# MB9BF11xT register map
File version: 1.7
Registers are 32-bit, read-write, reset 0x0 unless marked. A register's access mark holds for its fields unless they carry their own. Offsets are from the block's base; [hi:lo] are bit positions; {n}, {i} and the like mark numbered series; 'fields as' and 'values as' point back to an identical list.

## WC — Watch Counter
Base 0x4003A000
0x00 WCRD 8-bit ro — Watch Counter Read Register
  [5:0] CTR — counter value
0x01 WCRL 8-bit — Watch Counter Reload Register
  [5:0] RLC — reload value
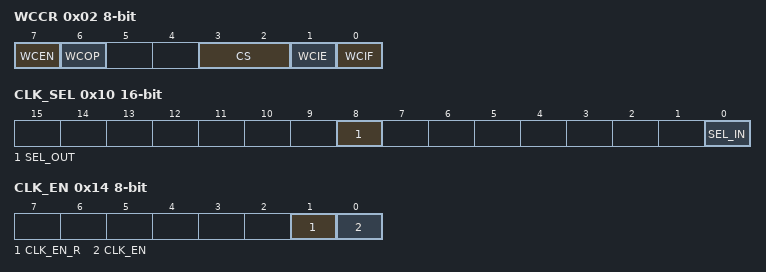
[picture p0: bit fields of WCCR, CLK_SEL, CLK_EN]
0x02 WCCR 8-bit — Watch Counter Control Register
  [7] WCEN — Watch counter operation enable bit
  [6] WCOP ro — Watch counter operating state flag
  [3:2] CS — Count clock select bits
  [1] WCIE — Interrupt request enable bit
  [0] WCIF — Interrupt request flag bit
0x10 CLK_SEL 16-bit — Clock Selection Register
  [8] SEL_OUT — Output clock selection bit
  [0] SEL_IN — Input clock selection bit
0x14 CLK_EN 8-bit — Division Clock Enable Register
  [1] CLK_EN_R — Division clock enable read bit
  [0] CLK_EN — Division clock enable bit

## EXTI — External Interrupt and NMI Control
Base 0x40030000
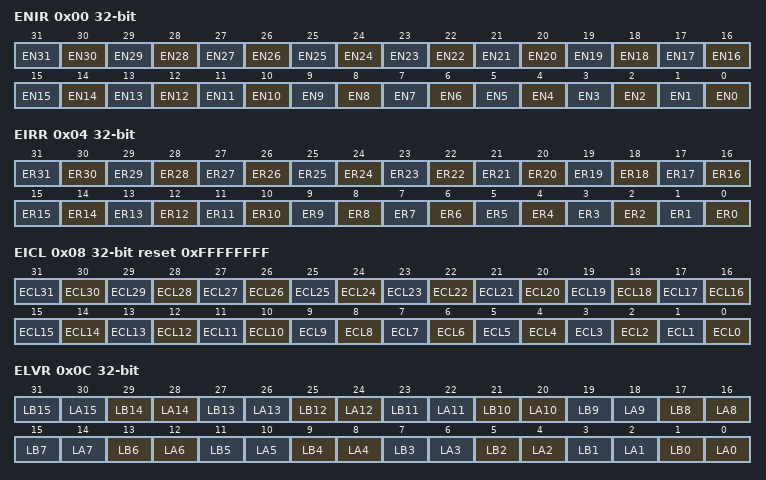
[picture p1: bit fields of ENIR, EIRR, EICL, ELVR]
0x00 ENIR — Enable Interrupt Request Register
  [n] EN{n} (n=0..31) — Bit{n} of ENIR
0x04 EIRR ro reset not defined — External Interrupt Request Register
  [n] ER{n} (n=0..31) — Bit{n} of EIRR
0x08 EICL reset 0xFFFFFFFF — External Interrupt Clear Register
  [n] ECL{n} (n=0..31) — Bit{n} of EICL
0x0C ELVR — External Interrupt Level Register
  [2n+1] LB{n} (n=0..15) — Bit{2n+1} of ELVR
  [2n] LA{n} (n=0..15) — Bit{2n} of ELVR
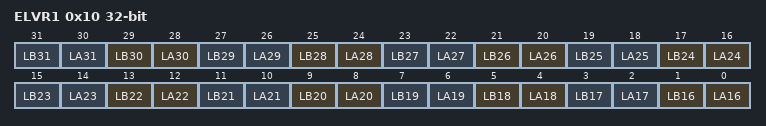
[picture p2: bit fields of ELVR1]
0x10 ELVR1 — External Interrupt Level Register 1
  [2n-31] LB{n} (n=16..31) — Bit{2n-31} of ELVR1
  [2n-32] LA{n} (n=16..31) — Bit{2n-32} of ELVR1
0x14 NMIRR 8-bit ro — Non Maskable Interrupt Request Register
  [0] NR — NMI interrupt request detection bit
0x18 NMICL 8-bit reset 0x1 — Non Maskable Interrupt Clear Register
  [0] NCL — NMI interrupt cause clear bit

## LVD — Low-voltage Detection
Base 0x40035000
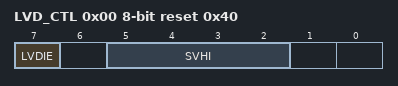
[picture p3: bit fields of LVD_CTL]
0x00 LVD_CTL 8-bit reset 0x40 — Low-voltage Detection Voltage Control Register
  [7] LVDIE — Low-voltage detection interrupt enable bit
  [5:2] SVHI — Low-voltage detection interrupt voltage setting bits
0x04 LVD_STR 8-bit ro — Low-voltage Detection Interrupt Register
  [7] LVDIR — Low-voltage detection interrupt bit
0x08 LVD_CLR 8-bit reset 0x80 — Low-voltage Detection Interrupt Clear Register
  [7] LVDCL — Low-voltage detection interrupt clear bit
0x0C LVD_RLR reset 0x1 — Low-voltage Detection Voltage Protection Register
  [31:0] LVDLCK — Low-voltage Detection Voltage Control Register protection bits
0x10 LVD_STR2 8-bit ro reset 0x40 — Low-voltage Detection Circuit Status Register
  [7] LVDIRDY — Low-voltage detection interrupt status flag

## MFS_NFC — I2C Auxiliary Noise Filter Setting Register
Base 0x40038800
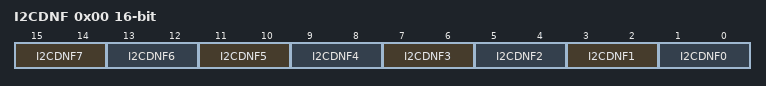
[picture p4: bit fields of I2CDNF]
0x00 I2CDNF 16-bit — I2C Auxiliary Noise Filter Setting Register
  [15:14] I2CDNF7 — Auxiliary noise filter additional step select bits for I2C ch.7
  [13:12] I2CDNF6 — Auxiliary noise filter additional step select bits for I2C ch.6
  [11:10] I2CDNF5 — Auxiliary noise filter additional step select bits for I2C ch.5
  [9:8] I2CDNF4 — Auxiliary noise filter additional step select bits for I2C ch.4
  [7:6] I2CDNF3 — Auxiliary noise filter additional step select bits for I2C ch.3
  [5:4] I2CDNF2 — Auxiliary noise filter additional step select bits for I2C ch.2
  [3:2] I2CDNF1 — Auxiliary noise filter additional step select bits for I2C ch.1
  [1:0] I2CDNF0 — Auxiliary noise filter additional step select bits for I2C ch.0

## CRC — CRC Registers
Base 0x40039000
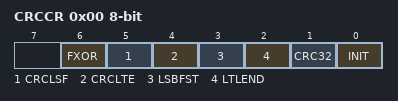
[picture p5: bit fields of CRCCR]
0x00 CRCCR 8-bit — CRC Control Register
  [6] FXOR — Initialization bit
  [5] CRCLSF — Final XOR control bit
  [4] CRCLTE — CRC result bit-order setting bit
  [3] LSBFST — CRC result byte-order setting bit
  [2] LTLEND — Bit-order setting bit
  [1] CRC32 — Byte-order setting bit
  [0] INIT — CRC mode selection bit
0x04 CRCINIT reset 0xFFFFFFFF — Initial Value Register
  [31:0] D — Initial value
0x08 CRCIN — Input Data Register
  [31:0] D — Input data
0x0C CRCR ro reset 0xFFFFFFFF — CRC Register
  [31:0] D — CRC Data

## EXBUS — External Bus Interface
Base 0x4003F000
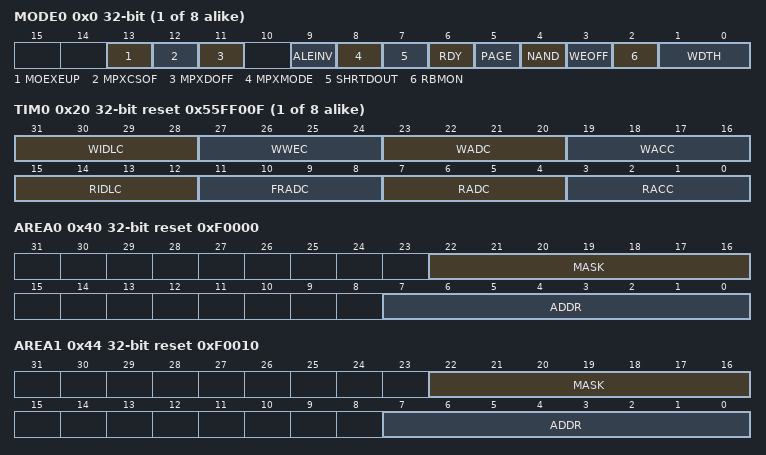
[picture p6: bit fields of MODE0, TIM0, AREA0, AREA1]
{0x0+4i} MODE{i} (i=0..7) — Mode Register {i}
  [13] MOEXEUP — select how to set the MOEX width
  [12] MPXCSOF — select a CS assertion from the start of accessing to the end of address output
  [11] MPXDOFF — select whether or not the address is output to the data lines in multiplex mode
  [9] ALEINV — set up the polarity of the ALE signal
  [8] MPXMODE — select operation bus mode
  [7] SHRTDOUT — select to which idle cycle the write data output is extended
  [6] RDY — control the external RDY function
  [5] PAGE — NOR Flash memory page access mode
  [4] NAND — NAND Flash memory mode
  [3] WEOFF — disable the write enable signal (MWEX) operation
  [2] RBMON — Read Byte Mask ON
  [1:0] WDTH — specify Data Width
{0x20+4i} TIM{i} reset 0x55FF00F (i=0..7) — Timing Register {i}
  [31:28] WIDLC — Write Idle Cycle
  [27:24] WWEC — Write Enable Cycle
  [23:20] WADC — Write Address Setup cycle
  [19:16] WACC — Write Access Cycle
  [15:12] RIDLC — Read Idle Cycle
  [11:8] FRADC — First Read Address Cycle
  [7:4] RADC — Read Address Setup cycle
  [3:0] RACC — Read Access Cycle
0x40 AREA0 reset 0xF0000 — Area Register 0
  [22:16] MASK — address mask
  [7:0] ADDR — Address
0x44 AREA1 reset 0xF0010 — Area Register 1
  [22:16] MASK — address mask
  [7:0] ADDR — Address
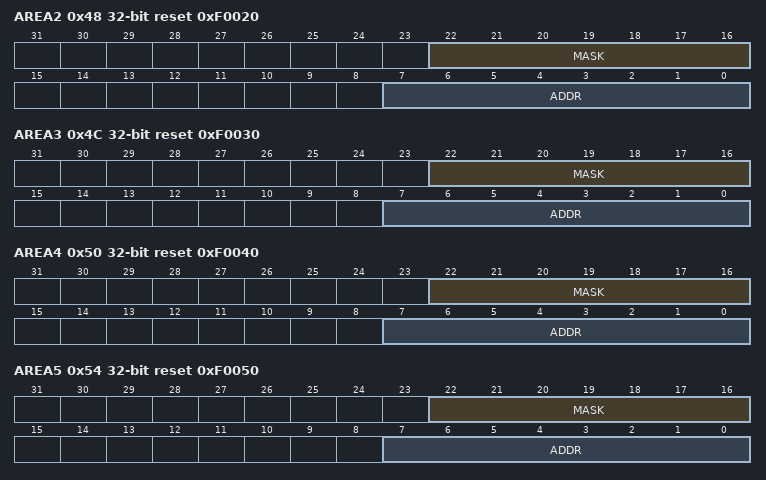
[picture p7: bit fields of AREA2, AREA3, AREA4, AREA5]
0x48 AREA2 reset 0xF0020 — Area Register 2
  [22:16] MASK — address mask
  [7:0] ADDR — Address
0x4C AREA3 reset 0xF0030 — Area Register 3
  [22:16] MASK — address mask
  [7:0] ADDR — Address
0x50 AREA4 reset 0xF0040 — Area Register 4
  [22:16] MASK — address mask
  [7:0] ADDR — Address
0x54 AREA5 reset 0xF0050 — Area Register 5
  [22:16] MASK — address mask
  [7:0] ADDR — Address
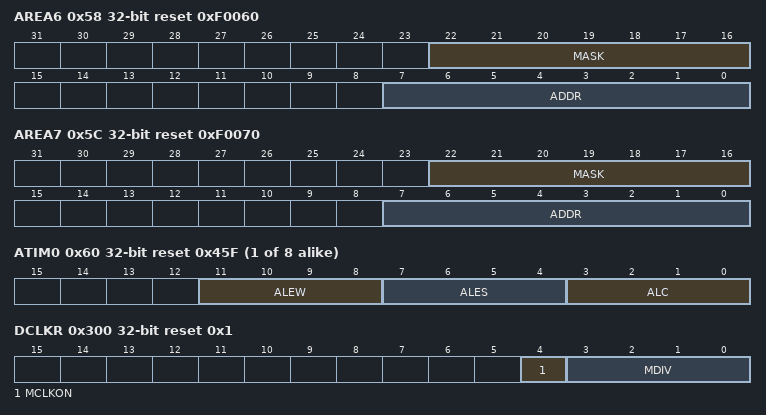
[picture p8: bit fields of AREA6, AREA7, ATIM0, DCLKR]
0x58 AREA6 reset 0xF0060 — Area Register 6
  [22:16] MASK — address mask
  [7:0] ADDR — Address
0x5C AREA7 reset 0xF0070 — Area Register 7
  [22:16] MASK — address mask
  [7:0] ADDR — Address
{0x60+4i} ATIM{i} reset 0x45F (i=0..7) — ALE Timing Register {i}
  [11:8] ALEW — Address Latch Enable Width
  [7:4] ALES — Address Latch Enable Setup cycle
  [3:0] ALC — Address Latch Cycle
0x300 DCLKR reset 0x1 (reset mask 0xF) — Division Clock Register
  [4] MCLKON
  [3:0] MDIV — MCLK Division Ratio Setup

## DMAC — DMAC Registers
Base 0x40060000
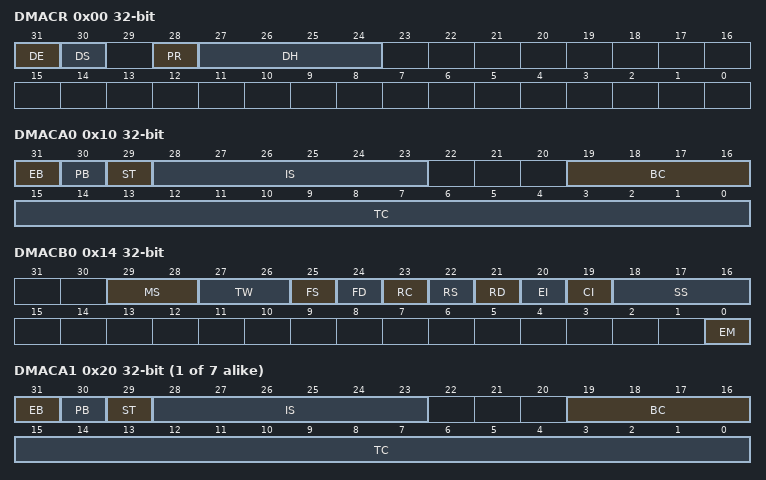
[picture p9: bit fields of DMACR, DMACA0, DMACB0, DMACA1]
0x00 DMACR — Entire DMAC Configuration Register
  [31] DE — DMA Enable (all-channel operation enable bit)
  [30] DS — DMA Stop
  [28] PR — Priority Rotation
  [27:24] DH — DMA Halt (All-channel pause bit)
0x10 DMACA0 — Configuration A Register
  [31] EB — Enable bit (individual-channel operation enable bit)
  [30] PB — Pause bit (individual-channel pause bit)
  [29] ST — Software Trigger
  [28:23] IS — Input Select
  [19:16] BC — Block Count
  [15:0] TC — Transfer Count
0x14 DMACB0 — Configuration B Register
  [29:28] MS — Mode Select
  [27:26] TW — Transfer Width
  [25] FS — Fixed Source
  [24] FD — Fixed Destination
  [23] RC — Reload Count (BC/TC reload)
  [22] RS — Reload Source
  [21] RD — Reload Destination
  [20] EI — Error Interrupt (unsuccessful transfer completion interrupt enable)
  [19] CI — Completion Interrupt (successful transfer completion interrupt enable)
  [18:16] SS — Stop Status (stop status notification)
  [0] EM — Enable bit Mask (EB bit clear mask)
0x18 DMACSA0 — Transfer Source Address Register
0x1C DMACDA0 — Transfer Destination Address Register
{0x10+0x10*i} DMACA{i} (i=1..7) — Configuration A Register {i}
  fields as DMACA0
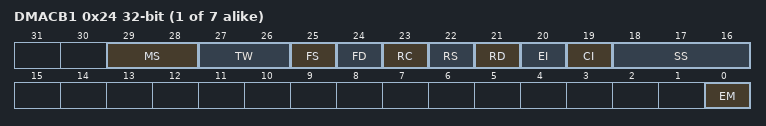
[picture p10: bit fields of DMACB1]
{0x14+0x10*i} DMACB{i} (i=1..7) — Configuration B Register {i}
  fields as DMACB0
{0x18+0x10*i} DMACSA{i} (i=1..7) — Transfer Source Address Register {i}
{0x1C+0x10*i} DMACDA{i} (i=1..7) — Transfer Destination Address Register {i}

## Notices in the file
Licence Terms
FUJITSU SEMICONDUCTOR LIMITED (gLICENSORh) hereby grants and
you (gLICENSEEh) hereby accept a non transferable, non-exclusive
licence to use and copy the deliverables (gDeliverablesh) solely for
the purpose of; (i) developing LICENSEEfs development tools and
distributing such development tools to third parties; (ii) generating
derivative representations of the Deliverables to develop and debug
software for LICENSORfs targeted devices or device series identified
within the Deliverables, (together the gPurposeh) under the following
terms and conditions:
1. Ownership.
The Deliverables are the property of LICENSOR. LICENSEE acquires no
right, title or interest in the Deliverables other than the licence
rights granted herein.
2. Use.
LICENSEE shall only be permitted to use the Deliverables for the
Purpose. LICENSEE shall not reverse engineer, decompile or
disassemble the Deliverables, in whole or in part.
3. Copies.
All copies of the Deliverables must bear the same notice(s) contained
on the original copies of the Deliverables.
4. No Warranty.
THE DELIVERABLES ARE PROVIDED gAS ISh AND ANY EXPRESS, IMPLIED OR
STATUTORY WARRANTIES, INCLUDING, BUT NOT LIMITED TO, THE IMPLIED
WARRANTIES OF MERCHANTABILITY, SATISFACTORY QUALITY AND FITNESS FOR
A PARTICULAR PURPOSE ARE DISCLAIMED.
IN NO EVENT SHALL LICENSOR BE LIABLE FOR ANY DIRECT, INDIRECT,
INCIDENTAL, SPECIAL, EXEMPLARY, OR CONSEQUENTIAL DAMAGES HOWEVER CAUSED
AND ON ANY THEORY OF LIABILITY, WHETHER IN CONTRACT, STRICT LIABILITY,
OR TORT (INCLUDING NEGLIGENCE OR OTHERWISE) ARISING IN ANY WAY OUT OF
THE USE OF THE DELIVERABLES, EVEN IF ADVISED OF THE POSSIBILITY OF SUCH
DAMAGE.
LICENSEE EXPRESSLY ASSUMES ALL LIABILITIES AND RISKS, FOR USE OR
OPERATION OF THE DELIVERABLES.
5.In the event that LICENSEE receives early access to the Deliverables,
LICENSEE acknowledges and agrees that;
(a) notwithstanding the licence grants above, LICENSEE shall only be
permitted to use the Deliverables solely internally for evaluation and
providing feedback to LICENSOR;
(b) except with respect to the limited licence grants in 5(a), LICENSEE
shall be subject to all of the terms and conditions set out above; and
(c) the Deliverables are confidential information and LICENSEE shall
maintain in confidence the Deliverables and apply security measures no
less stringent than the measures that LICENSEE applies to its own like
information, but not less than a reasonable degree of care, to prevent
unauthorised disclosure and use of the Deliverables.
